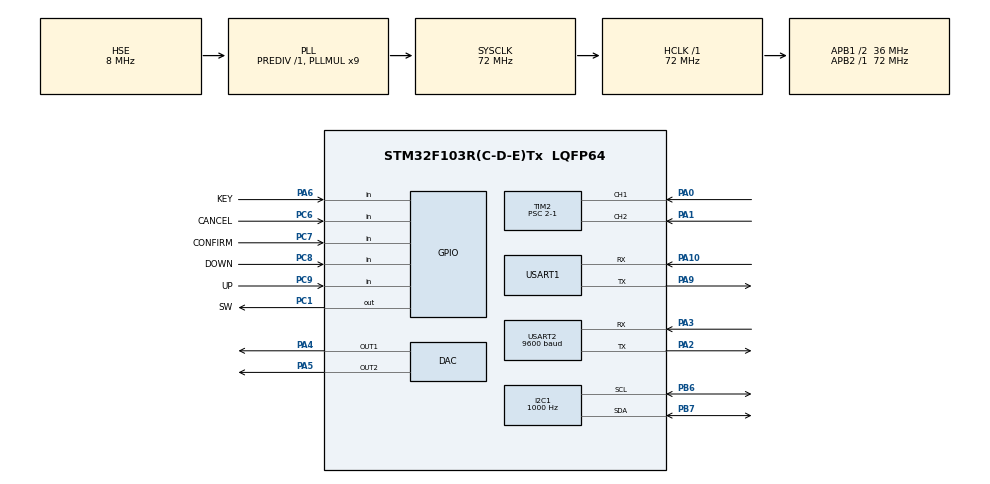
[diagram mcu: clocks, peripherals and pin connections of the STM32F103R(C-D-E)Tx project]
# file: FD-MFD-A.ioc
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I2C1.ClockSpeed=1000
I2C1.I2C_Mode=I2C_Standard
Mcu.Family=STM32F1
Mcu.Name=STM32F103R(C-D-E)Tx
Mcu.Package=LQFP64
NVIC.PriorityGroup=NVIC_PRIORITYGROUP_4
NVIC.TIM3_IRQn=true\:1\:0\:true\:false\:true\:true\:true\:true
NVIC.TIM4_IRQn=true\:2\:0\:true\:false\:true\:true\:true\:true
NVIC.TIM5_IRQn=true\:3\:0\:true\:false\:true\:true\:true\:true
NVIC.TIM6_IRQn=true\:4\:0\:true\:false\:true\:true\:true\:true
PA0-WKUP.Signal=S_TIM2_CH1_ETR
PA1.Signal=S_TIM2_CH2
PA10.Mode=Asynchronous
PA10.Signal=USART1_RX
PA2.Mode=Asynchronous
PA2.Signal=USART2_TX
PA3.Mode=Asynchronous
PA3.Signal=USART2_RX
PA4.Signal=COMP_DAC1_group
PA5.Signal=COMP_DAC2_group
PA6.GPIO_Label=KEY
PA6.GPIO_PuPd=GPIO_PULLUP
PA6.Signal=GPIO_Input
PA9.Mode=Asynchronous
PA9.Signal=USART1_TX
PB6.Mode=I2C
PB6.Signal=I2C1_SCL
PB7.Mode=I2C
PB7.Signal=I2C1_SDA
PC1.GPIO_Label=SW
PC1.GPIO_PuPd=GPIO_PULLDOWN
PC1.Signal=GPIO_Output
PC6.GPIO_Label=CANCEL
PC6.GPIO_PuPd=GPIO_PULLUP
PC6.Signal=GPIO_Input
PC7.GPIO_Label=CONFIRM
PC7.GPIO_PuPd=GPIO_PULLUP
PC7.Signal=GPIO_Input
PC8.GPIO_Label=DOWN
PC8.GPIO_PuPd=GPIO_PULLUP
PC8.Signal=GPIO_Input
PC9.GPIO_Label=UP
PC9.GPIO_PuPd=GPIO_PULLUP
PC9.Signal=GPIO_Input
PD0-OSC_IN.Mode=HSE-External-Oscillator
PD0-OSC_IN.Signal=RCC_OSC_IN
PD1-OSC_OUT.Mode=HSE-External-Oscillator
PD1-OSC_OUT.Signal=RCC_OSC_OUT
ProjectManager.HeapSize=0x200
ProjectManager.StackSize=0x400
ProjectManager.TargetToolchain=MDK-ARM V5.32
RCC.AHBFreq_Value=72000000
RCC.APB1CLKDivider=RCC_HCLK_DIV2
RCC.APB1Freq_Value=36000000
RCC.APB1TimFreq_Value=72000000
RCC.APB2Freq_Value=72000000
RCC.APB2TimFreq_Value=72000000
RCC.HCLKFreq_Value=72000000
RCC.PLLMUL=RCC_PLL_MUL9
RCC.PLLSourceVirtual=RCC_PLLSOURCE_HSE
RCC.SYSCLKFreq_VALUE=72000000
RCC.SYSCLKSource=RCC_SYSCLKSOURCE_PLLCLK
RCC.USBFreq_Value=72000000
SH.COMP_DAC1_group.0=DAC_OUT1,DAC_OUT1
SH.COMP_DAC2_group.0=DAC_OUT2,DAC_OUT2
SH.S_TIM2_CH1_ETR.0=TIM2_CH1,Encoder_Interface
SH.S_TIM2_CH2.0=TIM2_CH2,Encoder_Interface
TIM2.Prescaler=2-1
TIM3.Period=100-1
TIM3.Prescaler=7200-1
TIM4.Period=100-1
TIM4.Prescaler=7200-1
TIM5.Period=100-1
TIM5.Prescaler=7200-1
TIM6.Period=100-1
TIM6.Prescaler=7200-1
USART1.VirtualMode=VM_ASYNC
USART2.BaudRate=9600
USART2.VirtualMode=VM_ASYNC
VP_SYS_VS_ND.Mode=No_Debug
VP_TIM3_VS_ClockSourceINT.Mode=Internal
VP_TIM4_VS_ClockSourceINT.Mode=Internal
VP_TIM5_VS_ClockSourceINT.Mode=Internal
VP_TIM6_VS_ClockSourceINT.Mode=Enable_Timer
board=custom

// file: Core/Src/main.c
/* USER CODE BEGIN Header */
/**
  ******************************************************************************
  * @file           : main.c
  * @brief          : Main program body
  ******************************************************************************
  * @attention
  *
  * Copyright (c) 2025 STMicroelectronics.
  * All rights reserved.
  *
  * This software is licensed under terms that can be found in the LICENSE file
  * in the root directory of this software component.
  * If no LICENSE file comes with this software, it is provided AS-IS.
  *
  ******************************************************************************
  */
/* USER CODE END Header */
#include "main.h"
#include "dac.h"
#include "i2c.h"
#include "tim.h"
#include "usart.h"
#include "gpio.h"

/* USER CODE BEGIN Includes */
#include "FILE_SYS.H"
#include "ch376.h"
#include "flash.h"
#include "G85hal.h"
#include "menu.h"
#include "key.h"
/* USER CODE END Includes */

/* USER CODE BEGIN PD */
int fputc(int ch, FILE* file)
{
    HAL_UART_Transmit(&huart1,(uint8_t*)&ch,1,0xffff);
    return ch;
}
/* USER CODE END PD */

void SystemClock_Config(void);

int main(void)
{

  /* MCU Configuration--------------------------------------------------------*/

  /* Reset of all peripherals, Initializes the Flash interface and the Systick. */
  HAL_Init();

  /* USER CODE BEGIN Init */
	HAL_Delay(100);
  /* USER CODE END Init */

  /* Configure the system clock */
  SystemClock_Config();

  /* Initialize all configured peripherals */
  MX_GPIO_Init();
  MX_DAC_Init();
  MX_USART1_UART_Init();
  MX_USART2_UART_Init();
  MX_I2C1_Init();
  MX_TIM2_Init();
  MX_TIM3_Init();
  MX_TIM4_Init();
  MX_TIM5_Init();
  MX_TIM6_Init();
  /* USER CODE BEGIN 2 */

		system_init();
//		printf("page 11\xff\xff\xff");
//		page=GENERATE_COORDINATES;
//		HAL_GPIO_WritePin(SW_GPIO_Port,SW_Pin,GPIO_PIN_SET);
//		ch376_init();
//		ch376_writetest();
  /* USER CODE END 2 */

  /* Infinite loop */
  while (1)
  {

  }
}

void SystemClock_Config(void)
{
  RCC_OscInitTypeDef RCC_OscInitStruct = {0};
  RCC_ClkInitTypeDef RCC_ClkInitStruct = {0};

  /** Initializes the RCC Oscillators according to the specified parameters
  * in the RCC_OscInitTypeDef structure.
  */
  RCC_OscInitStruct.OscillatorType = RCC_OSCILLATORTYPE_HSE;
  RCC_OscInitStruct.HSEState = RCC_HSE_ON;
  RCC_OscInitStruct.HSEPredivValue = RCC_HSE_PREDIV_DIV1;
  RCC_OscInitStruct.HSIState = RCC_HSI_ON;
  RCC_OscInitStruct.PLL.PLLState = RCC_PLL_ON;
  RCC_OscInitStruct.PLL.PLLSource = RCC_PLLSOURCE_HSE;
  RCC_OscInitStruct.PLL.PLLMUL = RCC_PLL_MUL9;
  if (HAL_RCC_OscConfig(&RCC_OscInitStruct) != HAL_OK)
  {
    Error_Handler();
  }

  /** Initializes the CPU, AHB and APB buses clocks
  */
  RCC_ClkInitStruct.ClockType = RCC_CLOCKTYPE_HCLK|RCC_CLOCKTYPE_SYSCLK
                              |RCC_CLOCKTYPE_PCLK1|RCC_CLOCKTYPE_PCLK2;
  RCC_ClkInitStruct.SYSCLKSource = RCC_SYSCLKSOURCE_PLLCLK;
  RCC_ClkInitStruct.AHBCLKDivider = RCC_SYSCLK_DIV1;
  RCC_ClkInitStruct.APB1CLKDivider = RCC_HCLK_DIV2;
  RCC_ClkInitStruct.APB2CLKDivider = RCC_HCLK_DIV1;

  if (HAL_RCC_ClockConfig(&RCC_ClkInitStruct, FLASH_LATENCY_2) != HAL_OK)
  {
    Error_Handler();
  }
}

void Error_Handler(void)
{
  __disable_irq();
  while (1)
  {
  }
}
